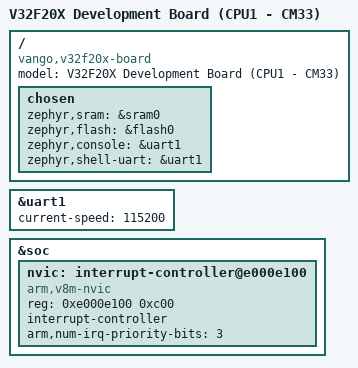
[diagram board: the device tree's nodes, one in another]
/dts-v1/;
#include <arm/vango/v32f20x/v32f20x.dtsi>

/ {
    model = "V32F20X Development Board (CPU1 - CM33)";
    compatible = "vango,v32f20x-board";

    chosen {
        zephyr,sram = &sram0;
        zephyr,flash = &flash0;
        zephyr,console = &uart1;
        zephyr,shell-uart = &uart1;
    };
};

&uart1 {
    status = "okay";
    current-speed = <115200>;
};

&soc {
    nvic: interrupt-controller@e000e100 {
        compatible = "arm,v8m-nvic";
        reg = <0xe000e100 0xc00>;
        interrupt-controller;
        #interrupt-cells = <2>;
        arm,num-irq-priority-bits = <3>;
    };
};
